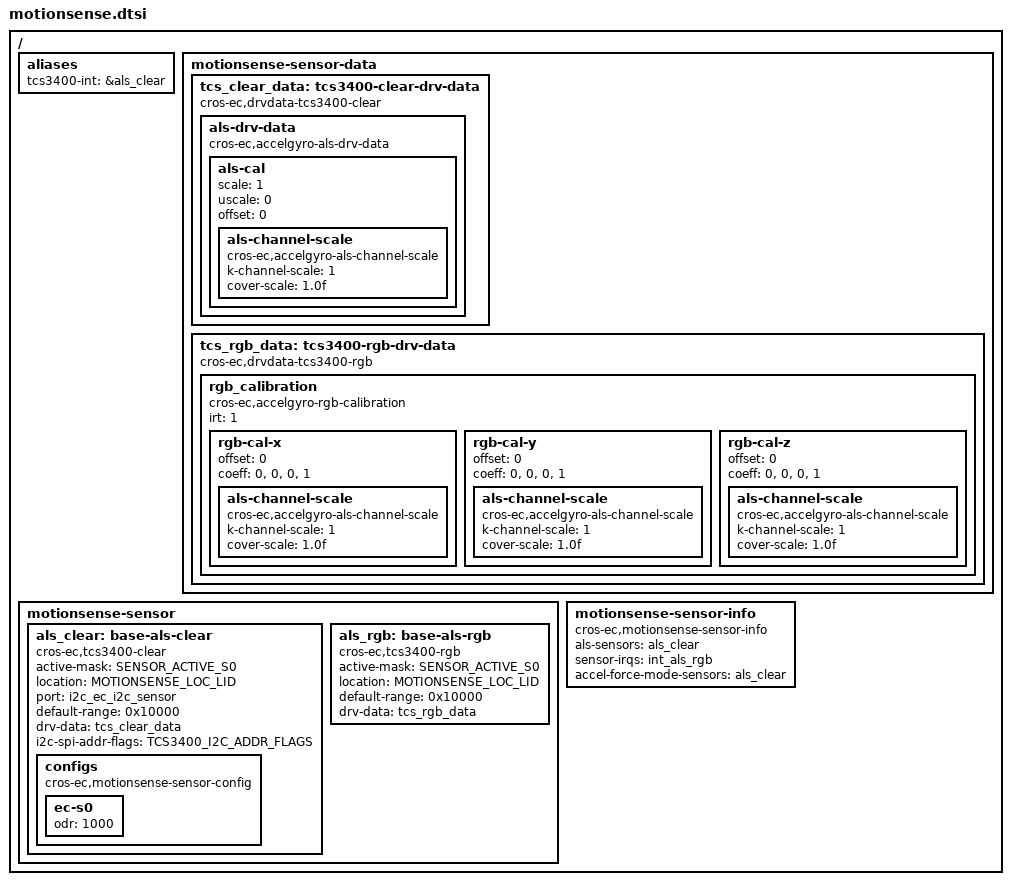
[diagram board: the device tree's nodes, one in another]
/* Copyright 2025 The ChromiumOS Authors
 * Use of this source code is governed by a BSD-style license that can be
 * found in the LICENSE file.
 */

#include <dt-bindings/motionsense/utils.h>


/ {
	aliases {
		tcs3400-int = &als_clear;
	};

	/* Rotation matrix used by drivers. */
	/delete-node/ motionsense-rotation-ref;
	motionsense-sensor-data {
		tcs_clear_data: tcs3400-clear-drv-data {
			compatible = "cros-ec,drvdata-tcs3400-clear";
			status = "okay";
			als-drv-data {
				compatible = "cros-ec,accelgyro-als-drv-data";
				als-cal {
					scale = <1>;
					uscale = <0>;
					offset = <0>;
					als-channel-scale {
					compatible =
					"cros-ec,accelgyro-als-channel-scale";
						k-channel-scale = <1>;
						cover-scale = "1.0f";
					};
				};
			};
		};
		tcs_rgb_data: tcs3400-rgb-drv-data {
			compatible = "cros-ec,drvdata-tcs3400-rgb";
			status = "okay";
			/* node for rgb_calibration_t defined in accelgyro.h */
			rgb_calibration {
				compatible =
					"cros-ec,accelgyro-rgb-calibration";
				irt = <1>;
				rgb-cal-x {
					offset = <0>;
					coeff = "0", "0", "0", "1";
					als-channel-scale {
					compatible =
					"cros-ec,accelgyro-als-channel-scale";
						k-channel-scale = <1>;
						cover-scale = "1.0f";
					};
				};
				rgb-cal-y {
					offset = <0>;
					coeff = "0", "0", "0", "1";
					als-channel-scale {
					compatible =
					"cros-ec,accelgyro-als-channel-scale";
						k-channel-scale = <1>;
						cover-scale = "1.0f";
					};
				};
				rgb-cal-z {
					offset = <0>;
					coeff = "0", "0", "0", "1";
					als-channel-scale {
					compatible =
					"cros-ec,accelgyro-als-channel-scale";
						k-channel-scale = <1>;
						cover-scale = "1.0f";
					};
				};
			};
		};
	};
	/*
	 * Declare mutexes used by sensor drivers.
	 * A mutex node is used to create an instance of mutex_t.
	 * A mutex node is referenced by a sensor node if the
	 * corresponding sensor driver needs to use the
	 * instance of the mutex.
	 */
	/delete-node/ motionsense-mutex;

	motionsense-sensor {
		als_clear: base-als-clear {
			compatible = "cros-ec,tcs3400-clear";
			status = "okay";

			active-mask = "SENSOR_ACTIVE_S0";
			location = "MOTIONSENSE_LOC_LID";
			port = <&i2c_ec_i2c_sensor>;
			default-range = <0x10000>;
			drv-data = <&tcs_clear_data>;
			i2c-spi-addr-flags = "TCS3400_I2C_ADDR_FLAGS";
			configs {
				compatible =
					"cros-ec,motionsense-sensor-config";
				ec-s0 {
					/* Run ALS sensor in S0 */
					odr = <1000>;
				};
			};
		};

		als_rgb: base-als-rgb {
			compatible = "cros-ec,tcs3400-rgb";
			status = "okay";

			active-mask = "SENSOR_ACTIVE_S0";
			location = "MOTIONSENSE_LOC_LID";
			default-range = <0x10000>; /* scale = 1x, uscale = 0 */
			drv-data = <&tcs_rgb_data>;
		};
	};

	motionsense-sensor-info {
		compatible = "cros-ec,motionsense-sensor-info";

		/* list of entries for motion_als_sensors */
		als-sensors = <&als_clear>;
		/*
		 * list of GPIO interrupts that have to
		 * be enabled at initial stage
		 */
		sensor-irqs = <&int_als_rgb>;
		/* list of sensors in force mode */
		accel-force-mode-sensors = <&als_clear>;
	};
};
